# ENCODER0_REG_TOPAZHP_CORE_0 register map
Vendor: Texas Instruments
Registers are 32-bit, access per field, reset 0x0 unless marked. A register's access mark holds for its fields unless they carry their own. Offsets are as the file gives them; [hi:lo] are bit positions; {n}, {i} and the like mark numbered series; <NAME> marks a mode.

## ENCODER0_REG_TOPAZHP_CORE_0 (part 2 of 2)
0x174 ENCODER0_CR_MVCALC_COLOCATED reset 0x100
  [10:0] CR_COL_DIST_SCALE_FACT rw — Singed scaling value in range -1024 to +1023 used to calculate direct mode motion vectors from co-located motion vector [a value of 256 uses co-located motion vector without scaling]
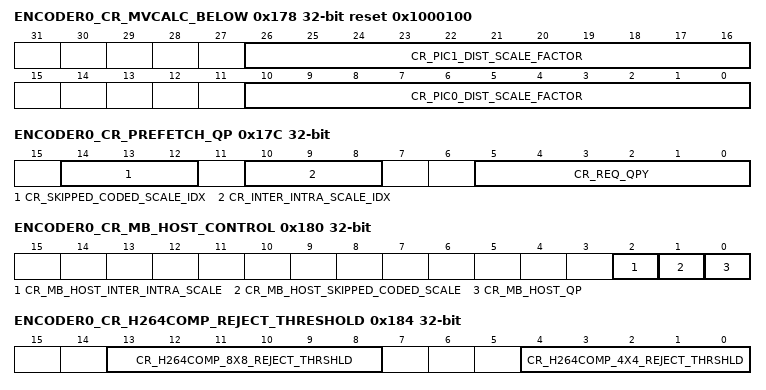
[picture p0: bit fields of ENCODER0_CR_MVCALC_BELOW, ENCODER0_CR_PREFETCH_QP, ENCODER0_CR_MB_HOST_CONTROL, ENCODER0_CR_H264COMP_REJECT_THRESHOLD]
0x178 ENCODER0_CR_MVCALC_BELOW reset 0x1000100
  [26:16] CR_PIC1_DIST_SCALE_FACTOR rw — Signed scaling factor in range -1024 to +1023 applied to below motion vector when calculating motion vector relative to reference picture 1
  [10:0] CR_PIC0_DIST_SCALE_FACTOR rw — Signed scaling factor in range -1024 to +1023 applied to below motion vector when calculating motion vector relative to reference picture 0 [intended for use when distance between frames when below motion vector was calculated is different from current distance between frames]
0x17C ENCODER0_CR_PREFETCH_QP — This register is used to set the requested QPy value at the start of the pipeline. Hardware keeps an internal version of requested QPy, which will propagate done the pipeline. Changes to this register will take effect at the start of the next kick.
  [14:12] CR_SKIPPED_CODED_SCALE_IDX rw — Index into skipped/coded scaling table
  [10:8] CR_INTER_INTRA_SCALE_IDX rw — Index into Inter/Intra scaling Table
  [5:0] CR_REQ_QPY rw — H
0x180 ENCODER0_CR_MB_HOST_CONTROL — Specify which macroblock parameters are valid in control structure read in from host
  [2] CR_MB_HOST_INTER_INTRA_SCALE rw — 0 - Inter/Intra scale table index for macroblock is specified by control registers
  [1] CR_MB_HOST_SKIPPED_CODED_SCALE rw — 0 - Skipped/Coded cost scaling for macroblock is specified by control registers
  [0] CR_MB_HOST_QP rw — 0 - Requested QP for macroblock [before CARC] is specified by control register [CR_REQ_QPY]
0x184 ENCODER0_CR_H264COMP_REJECT_THRESHOLD
  [13:8] CR_H264COMP_8X8_REJECT_THRSHLD rw — Threshold used to decide whether a 8x8 sub-block residual should be coded
  [4:0] CR_H264COMP_4X4_REJECT_THRSHLD rw — Threshold used to decide whether a 4x4 sub-block residual should be coded
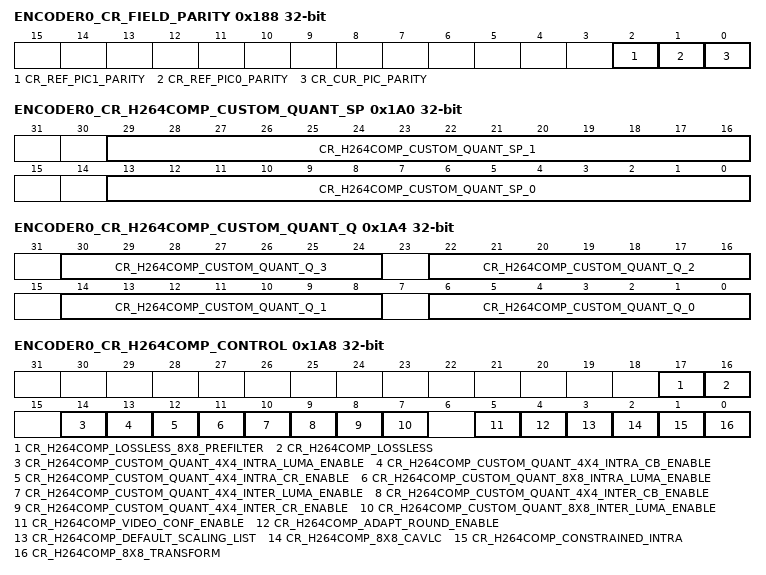
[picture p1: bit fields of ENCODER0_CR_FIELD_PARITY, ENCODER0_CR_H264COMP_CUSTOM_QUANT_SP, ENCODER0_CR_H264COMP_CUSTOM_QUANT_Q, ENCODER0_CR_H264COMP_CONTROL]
0x188 ENCODER0_CR_FIELD_PARITY
  [2] CR_REF_PIC1_PARITY rw — 0 - Top Field
  [1] CR_REF_PIC0_PARITY rw — 0 - Top Field
  [0] CR_CUR_PIC_PARITY rw — 0 - Top field
0x1A0 ENCODER0_CR_H264COMP_CUSTOM_QUANT_SP — This register is written repeatedly to store the Sp values for the Custom Quantisation Matrix. Two Sp values at a time are stored. The Sp values should be provided in raster order, with the 16 values for the 4x4 intra luma matrix provided first, followed by the 16 values for the 4x4 inter luma matrix, followed by the 16 values for the 4x4 intra Cb matrix, followed by the 16 values for the 4x4 inter Cb matrix, followed by the 16 values for the 4x4 intra Cr matrix, followed by the 16 values for the 4x4 inter Cr matrix, followed by the 64 values for the 8x8 intra luma matrix, followed by the 64 values for the 8x8 inter luma matrix. The 8x8 values do not need to be stored if use of the 8x8 transform is disabled. To store the full set of Sp values takes 112 register write accesses. To store only the 4x4 values takes 48 register write accesses. The format of this register is arranged such that Sp values packed 1 per 2 bytes in memory may be directly copied into the register.When read this register always returns 0x00000000.
  [29:16] CR_H264COMP_CUSTOM_QUANT_SP_1 rw — Sp value for Custom Quantisation Matrix.
  [13:0] CR_H264COMP_CUSTOM_QUANT_SP_0 rw — Sp value for Custom Quantisation Matrix.
0x1A4 ENCODER0_CR_H264COMP_CUSTOM_QUANT_Q — This register is written repeatedly to store the Q values for the Custom Quantisation Matrix. Four Q values at a time are stored. The Q values should be provided in raster order, with the 16 values for the 4x4 intra luma matrix provided first, followed by the 16 values for the 4x4 inter luma matrix, followed by the 16 values for the 4x4 intra Cb matrix, followed by the 16 values for the 4x4 inter Cb matrix, followed by the 16 values for the 4x4 intra Cr matrix, followed by the 16 values for the 4x4 inter Cr matrix, followed by the 64 values for the 8x8 intra luma matrix, followed by the 64 values for the 8x8 inter luma matrix. The 8x8 values do not need to be stored if use of the 8x8 transform is disabled. To store the full set of Q values takes 56 register write accesses. To store only the 4x4 values takes 24 register write accesses. The format of this register is arranged such that Q values packed 1 per byte in memory may be directly copied into the register.When read this register always returns 0x00000000.
  [8n+6:8n] CR_H264COMP_CUSTOM_QUANT_Q_{n} rw (n=0..3) — Q value for Custom Quantisation Matrix.
0x1A8 ENCODER0_CR_H264COMP_CONTROL
  [17] CR_H264COMP_LOSSLESS_8X8_PREFILTER rw — Controls whether the pre-filter operation should be performed as part of the Intra8x8 prediction in Lossless Mode.
  [16] CR_H264COMP_LOSSLESS rw — Controls support of lossless encoding in H.264.
  [14] CR_H264COMP_CUSTOM_QUANT_4X4_INTRA_LUMA_ENABLE rw — Controls the use of Custom Quantisation Tables for the following block types:
  [13] CR_H264COMP_CUSTOM_QUANT_4X4_INTRA_CB_ENABLE rw — Controls the use of Custom Quantisation Tables for the following block types:
  [12] CR_H264COMP_CUSTOM_QUANT_4X4_INTRA_CR_ENABLE rw — Controls the use of Custom Quantisation Tables for the following block types:
  [11] CR_H264COMP_CUSTOM_QUANT_8X8_INTRA_LUMA_ENABLE rw — Controls the use of Custom Quantisation Tables for the following block types:
  [10] CR_H264COMP_CUSTOM_QUANT_4X4_INTER_LUMA_ENABLE rw — Controls the use of Custom Quantisation Tables for the following block types:
  [9] CR_H264COMP_CUSTOM_QUANT_4X4_INTER_CB_ENABLE rw — Controls the use of Custom Quantisation Tables for the following block types:
  [8] CR_H264COMP_CUSTOM_QUANT_4X4_INTER_CR_ENABLE rw — Controls the use of Custom Quantisation Tables for the following block types:
  [7] CR_H264COMP_CUSTOM_QUANT_8X8_INTER_LUMA_ENABLE rw — Controls the use of Custom Quantisation Tables for the following block types:
  [5] CR_H264COMP_VIDEO_CONF_ENABLE rw — 0: Video conference support is disabled
  [4] CR_H264COMP_ADAPT_ROUND_ENABLE rw — 0: Use Fixed Rounding
  [3] CR_H264COMP_DEFAULT_SCALING_LIST rw — Controls the choice between FLAT and DEFAULT scaling lists.
  [2] CR_H264COMP_8X8_CAVLC rw — 0: If transform size is 8x8, CABAC mode is used, so don't need to re-order block coefficients into 4x4 blocks.
  [1] CR_H264COMP_CONSTRAINED_INTRA rw — 0: Intra prediction can use boundary pixels from Inter MBs
  [0] CR_H264COMP_8X8_TRANSFORM rw — 0: Use 4x4 transform for Inter MB, disable Luma Intra 8x8 prediction
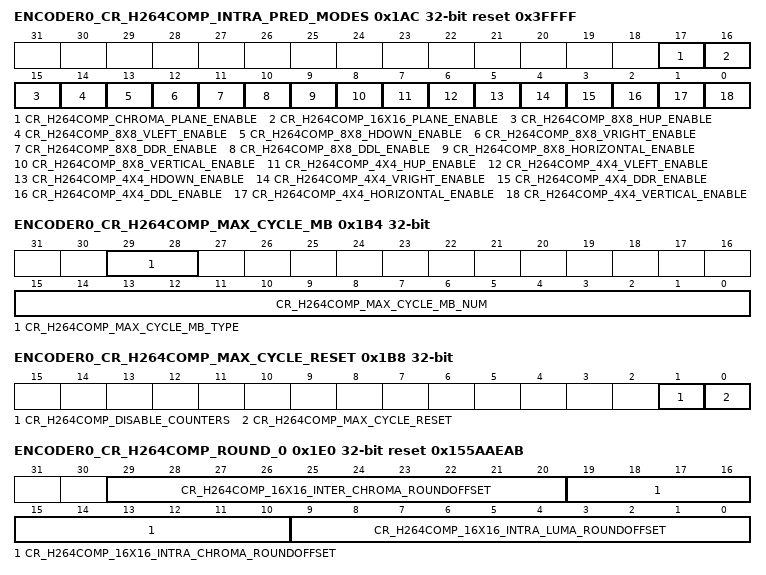
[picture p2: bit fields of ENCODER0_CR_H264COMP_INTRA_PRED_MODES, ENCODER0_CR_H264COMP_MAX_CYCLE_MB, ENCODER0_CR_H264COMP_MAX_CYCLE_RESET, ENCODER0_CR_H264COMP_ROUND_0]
0x1AC ENCODER0_CR_H264COMP_INTRA_PRED_MODES reset 0x3FFFF
  [17] CR_H264COMP_CHROMA_PLANE_ENABLE rw, [16] CR_H264COMP_16X16_PLANE_ENABLE rw, [15] CR_H264COMP_8X8_HUP_ENABLE rw, [14] CR_H264COMP_8X8_VLEFT_ENABLE rw, [13] CR_H264COMP_8X8_HDOWN_ENABLE rw, [12] CR_H264COMP_8X8_VRIGHT_ENABLE rw, [11] CR_H264COMP_8X8_DDR_ENABLE rw, [10] CR_H264COMP_8X8_DDL_ENABLE rw, [9] CR_H264COMP_8X8_HORIZONTAL_ENABLE rw, [8] CR_H264COMP_8X8_VERTICAL_ENABLE rw, [7] CR_H264COMP_4X4_HUP_ENABLE rw, [6] CR_H264COMP_4X4_VLEFT_ENABLE rw, [5] CR_H264COMP_4X4_HDOWN_ENABLE rw, [4] CR_H264COMP_4X4_VRIGHT_ENABLE rw, [3] CR_H264COMP_4X4_DDR_ENABLE rw, [2] CR_H264COMP_4X4_DDL_ENABLE rw, [1] CR_H264COMP_4X4_HORIZONTAL_ENABLE rw, [0] CR_H264COMP_4X4_VERTICAL_ENABLE rw
0x1B0 ENCODER0_CR_H264COMP_MAX_CYCLE_COUNT
  [15:0] CR_H264COMP_MAX_CYCLE_COUNT rw — The worst case cycle count of the MB processing for the cmprs module
0x1B4 ENCODER0_CR_H264COMP_MAX_CYCLE_MB
  [29:28] CR_H264COMP_MAX_CYCLE_MB_TYPE rw — It indicates the MB type: I, P or B of the worst MB processing cycle number
  [15:0] CR_H264COMP_MAX_CYCLE_MB_NUM rw — Number of the macroblock with the worst MB cycle count
0x1B8 ENCODER0_CR_H264COMP_MAX_CYCLE_RESET
  [1] CR_H264COMP_DISABLE_COUNTERS rw — When this bit is set to a 1, the max cycle counters should not be clocked
  [0] CR_H264COMP_MAX_CYCLE_RESET rw — To be used by MTX to reset the max cycle registers [0x01b0 and 0x01b4]
0x1BC ENCODER0_CR_H264COMP4X4_PRED_CRC rw
  [31:0] CR_H264COMP4X4_PRED_CRC — CRC value of the 4x4 prediction blocks
0x1C0 ENCODER0_CR_H264COMP4X4_COEFFS_CRC rw
  [31:0] CR_H264COMP4X4_COEFFS_CRC — CRC value of the 4x4 quantised coefficients
0x1C4 ENCODER0_CR_H264COMP4X4_RECON_CRC rw
  [31:0] CR_H264COMP4X4_RECON_CRC — CRC value of the 4x4 reconstructed blocks
0x1C8 ENCODER0_CR_H264COMP8X8_PRED_CRC rw
  [31:0] CR_H264COMP8X8_PRED_CRC — CRC value of the 8x8 prediction blocks
0x1CC ENCODER0_CR_H264COMP8X8_COEFFS_CRC rw
  [31:0] CR_H264COMP8X8_COEFFS_CRC — CRC value of the 8x8 quantised coefficients
0x1D0 ENCODER0_CR_H264COMP8X8_RECON_CRC rw
  [31:0] CR_H264COMP8X8_RECON_CRC — CRC value of the 8x8 reconstructed blocks
0x1D4 ENCODER0_CR_H264COMP16X16_PRED_CRC rw
  [31:0] CR_H264COMP16X16_PRED_CRC — CRC value of the 16x16 prediction blocks
0x1D8 ENCODER0_CR_H264COMP16X16_COEFFS_CRC rw
  [31:0] CR_H264COMP16X16_COEFFS_CRC — CRC value of the 16x16 quantised coefficients
0x1DC ENCODER0_CR_H264COMP16X16_RECON_CRC rw
  [31:0] CR_H264COMP16X16_RECON_CRC — CRC value of the 16x16 reconstructed blocks
0x1E0 ENCODER0_CR_H264COMP_ROUND_0 reset 0x155AAEAB — The rounding offset values should be written to / read from these registers between slices when the slice type is changed.A sequence of 3 reads or writes to this register should be performed in the following order: offset_1 -> offset_2 -> offset_3. Provided that a full sequence of 3 reads is performed the data stored will be left unchanged. The intra values all reset to 0x2AB (=1/3) and the inter values all reset to 0x155 (=1/6). They can also all be initialised to these values using a single write to ROUNDOFFSET_INITIALISE.
  [29:20] CR_H264COMP_16X16_INTER_CHROMA_ROUNDOFFSET rw — Adaptive rounding offset values for 16x16 inter chroma.
  [19:10] CR_H264COMP_16X16_INTRA_CHROMA_ROUNDOFFSET rw — Adaptive rounding offset values for 16x16 intra chroma.
  [9:0] CR_H264COMP_16X16_INTRA_LUMA_ROUNDOFFSET rw — Adaptive rounding offset values for 16x16 intra luma.
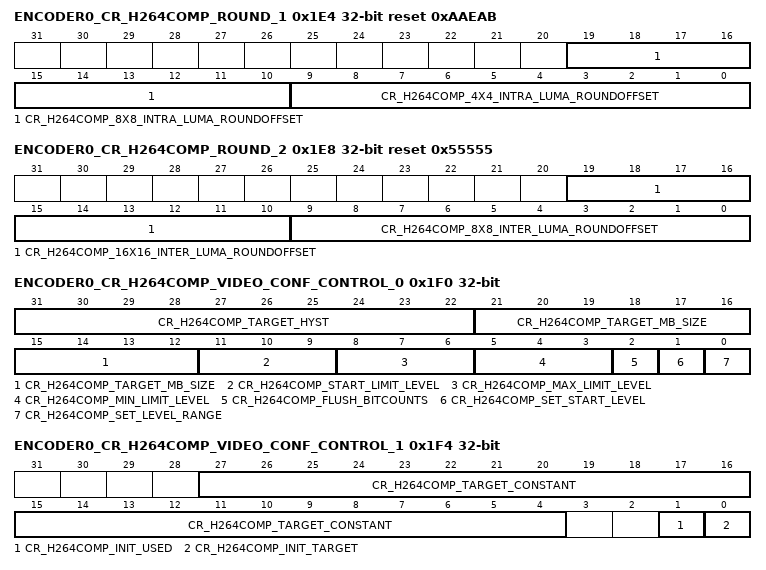
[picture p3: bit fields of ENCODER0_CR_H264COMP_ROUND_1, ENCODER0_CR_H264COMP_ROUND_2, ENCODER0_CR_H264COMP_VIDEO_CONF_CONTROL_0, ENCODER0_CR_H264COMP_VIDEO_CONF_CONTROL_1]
0x1E4 ENCODER0_CR_H264COMP_ROUND_1 reset 0xAAEAB — A sequence of 4 reads or writes to this register should be performed in the following order: offset_0 -> offset_1 -> offset_2 -> offset_3. Provided that a full sequence of 4 reads is performed the data stored will be left unchanged. The intra values all reset to 0x2AB (=1/3). They can also all be initialised to these values using a single write to ROUNDOFFSET_INITIALISE.
  [19:10] CR_H264COMP_8X8_INTRA_LUMA_ROUNDOFFSET rw — Adaptive rounding offset values for 8x8 intra luma.
  [9:0] CR_H264COMP_4X4_INTRA_LUMA_ROUNDOFFSET rw — Adaptive rounding offset values for 4x4 intra luma.
0x1E8 ENCODER0_CR_H264COMP_ROUND_2 reset 0x55555 — A sequence of 4 reads or writes to this register should be performed in the following order: offset_0 -> offset_1 -> offset_2 -> offset_3. Provided that a full sequence of 4 reads is performed the data stored will be left unchanged. The intra values all reset to 0x155 (=1/6). They can also all be initialised to these values using a single write to ROUNDOFFSET_INITIALISE.
  [19:10] CR_H264COMP_16X16_INTER_LUMA_ROUNDOFFSET rw — Adaptive rounding offset values for 16x16 inter luma.
  [9:0] CR_H264COMP_8X8_INTER_LUMA_ROUNDOFFSET rw — Adaptive rounding offset values for 8x8 inter luma.
0x1EC ENCODER0_CR_H264COMP_ROUND_INIT — Writing 0x1 to this register causes all of the rounding offsets to be initialised to their default values, which are 0x2AB (=1/3) for intra, and 0x155 (=1/6) for inter.
  [0] CR_H264COMP_ROUNDOFFSET_INITIALISE rw — 0: No effect
0x1F0 ENCODER0_CR_H264COMP_VIDEO_CONF_CONTROL_0 rw — Double buffered register for configuring the macroblock size control for video conference support. The feature is disabled when H264COMP_CONTROL/H264COMP_VIDEO_CONF_ENABLE = 0. 0
  [31:22] CR_H264COMP_TARGET_HYST — The number of bits below the target the used count has to be before the limit_level is decremented, see description for TARGET_MB_SIZE.
  [21:12] CR_H264COMP_TARGET_MB_SIZE — The target macroblock size to be achieved in bits cross a frame.
  [11:9] CR_H264COMP_START_LIMIT_LEVEL — Limit level to be used for the first macroblock in the BU.
  [8:6] CR_H264COMP_MAX_LIMIT_LEVEL — Maximum limit level to be used during the BU.
  [5:3] CR_H264COMP_MIN_LIMIT_LEVEL — Minimum limit level to be used during the BU.
  [2] CR_H264COMP_FLUSH_BITCOUNTS — 0: The FIFO which buffers the bitcounts between the VLC and the H264comp is NOT flushed.
  [1] CR_H264COMP_SET_START_LEVEL — 0: The limit level is allowed to increment or decrement depending on the bitcount target on all macroblocks in the BU, continuing on from the previous BU.
  [0] CR_H264COMP_SET_LEVEL_RANGE — 0: The maximum and minimum limit level are left unchanged.
0x1F4 ENCODER0_CR_H264COMP_VIDEO_CONF_CONTROL_1 — Double buffered register for configuring the macroblock size control for video conference support.
  [27:4] CR_H264COMP_TARGET_CONSTANT rw — Constant used in the calculation of the bitrate target, see TARGET_MB_SIZE.
  [1] CR_H264COMP_INIT_USED rw — 0: The count of bits used increases as usual on every macroblock.
  [0] CR_H264COMP_INIT_TARGET rw — 0: The bitcount target is incremented by TARGET_MB_SIZE on every macroblock.
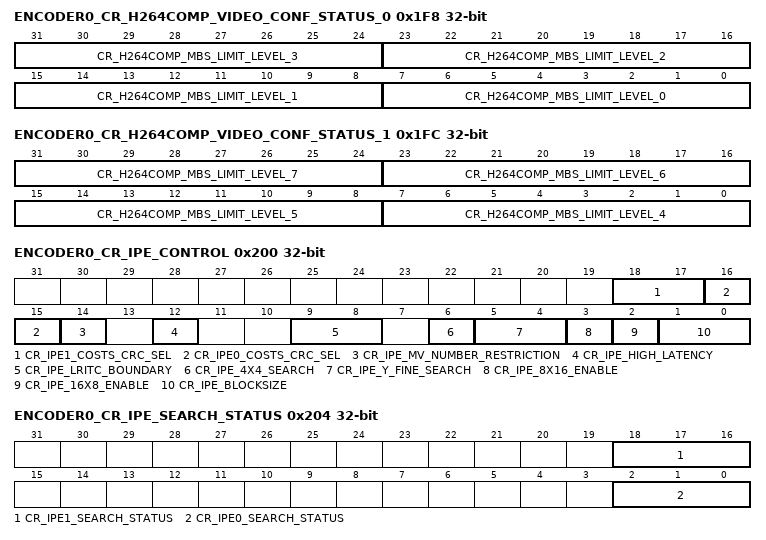
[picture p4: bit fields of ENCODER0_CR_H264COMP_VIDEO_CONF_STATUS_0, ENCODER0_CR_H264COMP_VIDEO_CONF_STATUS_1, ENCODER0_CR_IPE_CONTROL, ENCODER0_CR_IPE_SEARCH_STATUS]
0x1F8 ENCODER0_CR_H264COMP_VIDEO_CONF_STATUS_0 ro — Double buffered register providing status on how many macroblocks in the last BU were encoded at each limit level when video conference support is in use. This register will only update if video conference support is enabled.
  [8n+7:8n] CR_H264COMP_MBS_LIMIT_LEVEL_{n} (n=0..3) — The number of macroblocks in the last BU that were coded using LIMIT_LEVEL_{n}.
0x1FC ENCODER0_CR_H264COMP_VIDEO_CONF_STATUS_1 ro — Double buffered register providing status on how many macroblocks in the last BU were encoded at each limit level when video conference support is in use. This register will only update if video conference support is enabled.
  [8n-25:8n-32] CR_H264COMP_MBS_LIMIT_LEVEL_{n} (n=4..7) — The number of macroblocks in the last BU that were coded using LIMIT_LEVEL_{n}.
0x200 ENCODER0_CR_IPE_CONTROL
  [18:17] CR_IPE1_COSTS_CRC_SEL rw — selects between the different crcs, can be switched wile running, all crcs exist just share register space
  [16:15] CR_IPE0_COSTS_CRC_SEL rw — selects between the different crcs, can be switched wile running, all crcs exist just share register space
  [14] CR_IPE_MV_NUMBER_RESTRICTION rw
  [12] CR_IPE_HIGH_LATENCY rw — 0 : IPE 8x8 spatial candidates include previous 8x8 block
  [9:8] CR_IPE_LRITC_BOUNDARY rw — This field +1 defines number of boundary pixels LRITC needs to fetch for each block request.
  [6] CR_IPE_4X4_SEARCH rw — If IPE_BLOCKSIZE enables 4x4 search
  [5:4] CR_IPE_Y_FINE_SEARCH rw
  [3] CR_IPE_8X16_ENABLE rw — 0 : Disable 8x16 motion vector block size detection
  [2] CR_IPE_16X8_ENABLE rw — 0 : Disable 16x8 motion vector block size detection
  [1:0] CR_IPE_BLOCKSIZE rw
0x204 ENCODER0_CR_IPE_SEARCH_STATUS
  [18:16] CR_IPE1_SEARCH_STATUS rw — 000: Finished recieving candidates/Idle between MB's
  [2:0] CR_IPE0_SEARCH_STATUS rw — 000: Finished recieving candidates/Idle between MB's
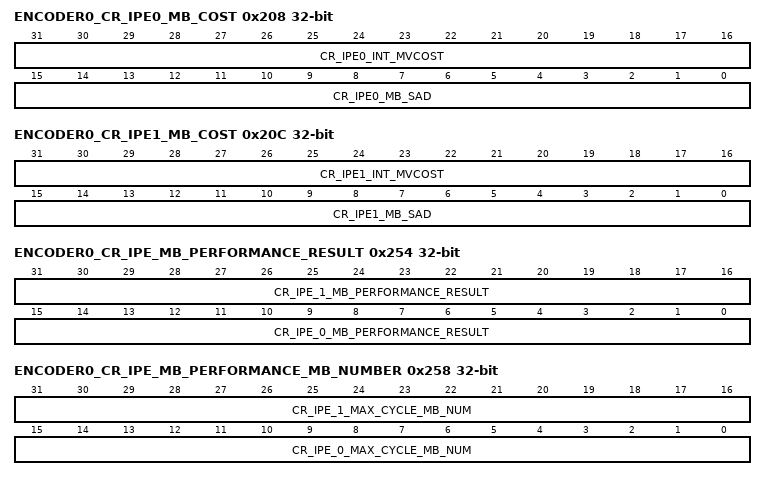
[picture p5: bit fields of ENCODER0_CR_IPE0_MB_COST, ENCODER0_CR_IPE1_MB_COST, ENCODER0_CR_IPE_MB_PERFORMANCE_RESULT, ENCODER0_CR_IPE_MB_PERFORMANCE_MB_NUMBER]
0x208 ENCODER0_CR_IPE0_MB_COST rw
  [31:16] CR_IPE0_INT_MVCOST — Total motion vector cost for IPE 0
  [15:0] CR_IPE0_MB_SAD — Total Sum of Absolute Differences value for IPE 0
0x20C ENCODER0_CR_IPE1_MB_COST rw
  [31:16] CR_IPE1_INT_MVCOST — Total motion vector cost for IPE 1
  [15:0] CR_IPE1_MB_SAD — Total Sum of Absolute Differences value for IPE 1
0x240 ENCODER0_CR_IPE0_BESTMV_CRC rw
  [31:0] CR_IPE0_BESTMV_CRC — IPE 0 CRC best mv data output.
0x244 ENCODER0_CR_IPE1_BESTMV_CRC rw
  [31:0] CR_IPE1_BESTMV_CRC — IPE 1 CRC best mv data output.
0x248 ENCODER0_CR_IPE0_COSTS_CRC rw
  [31:0] CR_IPE0_COSTS_CRC — IPE costs crc, crc for ipe costs, there is a select register to select between 4x4, 8x8 or 16x16 costs.
0x24C ENCODER0_CR_IPE1_COSTS_CRC rw
  [31:0] CR_IPE1_COSTS_CRC — IPE costs crc, for the second ipe, there is a select register to select between 4x4, 8x8 or 16x16 costs.
0x250 ENCODER0_CR_IPE_MB_PERFORMANCE_CLEAR — IPE macro block performance clear register
  [0] CR_IPE_MB_PERFORMANCE_CLEAR wo — Clear the ipe mb performance registers
0x254 ENCODER0_CR_IPE_MB_PERFORMANCE_RESULT ro — IPE macro block performance maximum cycle count (based on last done from either IPE 0 or IPE 1)
  [31:16] CR_IPE_1_MB_PERFORMANCE_RESULT — Maximum IPE 1 cycle count
  [15:0] CR_IPE_0_MB_PERFORMANCE_RESULT — Maximum IPE 0 cycle count
0x258 ENCODER0_CR_IPE_MB_PERFORMANCE_MB_NUMBER ro — IPE macro block performance macro block number
  [31:16] CR_IPE_1_MAX_CYCLE_MB_NUM — Number of macroblock with the worst case cycle count
  [15:0] CR_IPE_0_MAX_CYCLE_MB_NUM — Number of macroblock with the worst case cycle count
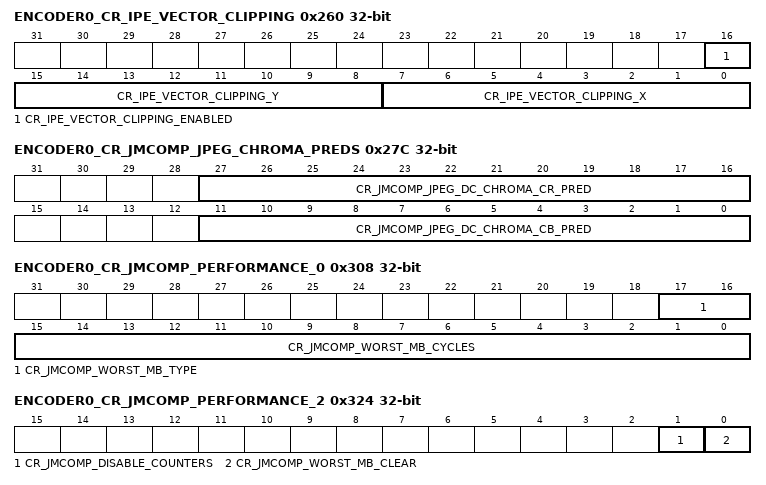
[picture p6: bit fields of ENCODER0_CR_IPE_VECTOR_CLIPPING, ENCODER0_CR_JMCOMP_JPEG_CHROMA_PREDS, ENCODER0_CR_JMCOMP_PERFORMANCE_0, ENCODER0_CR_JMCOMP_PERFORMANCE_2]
0x260 ENCODER0_CR_IPE_VECTOR_CLIPPING — This register contains the maximum X & Y vectors (normally used for MPEG4 and H263 encoding). The IPE module needs to take these values into account when searching for the best vector. This register is used by both the Prefetch Sequencer (to ensure initial candidates are within the clipping range) and by IPE (to ensure fine search and 4x4 search doesn't extend outside the clipping area), and by SPE (to ensure sub-pixel search doesn't extend outside the clipping area).
  [16] CR_IPE_VECTOR_CLIPPING_ENABLED rw — 0 : Ignore IPE vector clipping registers [only clip to maximum search range supported by hardware]
  [15:8] CR_IPE_VECTOR_CLIPPING_Y rw — Maximum Y vector [integer resolution]
  [7:0] CR_IPE_VECTOR_CLIPPING_X rw — Maximum X vector [integer resolution]
0x270 ENCODER0_CR_JMCOMP_CONTROL reset 0x8000
  [15] CR_JMCOMP_AC_ENABLE rw
0x278 ENCODER0_CR_JMCOMP_JPEG_LUMA_PRED
  [11:0] CR_JMCOMP_JPEG_DC_LUMA_PRED rw — Current Luma DC prediction
0x27C ENCODER0_CR_JMCOMP_JPEG_CHROMA_PREDS
  [27:16] CR_JMCOMP_JPEG_DC_CHROMA_CR_PRED rw — Current Cr DC prediction
  [11:0] CR_JMCOMP_JPEG_DC_CHROMA_CB_PRED rw — Current Cb DC prediction
{0x280+4i} ENCODER0_CR_JMCOMP_LUMA_QUANTISER_{i:02} rw (i=0..15)
  [31:24] CR_JMCOMP_LUMA_QUANT — 64 JPEG Luma quantisation coefficients
{0x2C0+4i} ENCODER0_CR_JMCOMP_CHROMA_QUANTISER_{i:02} rw (i=0..15)
  [31:24] CR_JMCOMP_CHROMA_QUANT — 64 JPEG Chroma quantisation coefficients [same coefficients used for Cb and Cr]
0x300 ENCODER0_CR_JMCOMP_CRC rw
  [31:0] CR_JMCOMP_CRC_OUT — CRC value of the current data that is written to the ESB
0x304 ENCODER0_CR_JMCOMP_VLC_CRC rw — CRC for data outputted to VLC
  [31:0] CR_JMCOMP_VLC_IF_CRC — CRC value of the coded data that is sent to the VLC
0x308 ENCODER0_CR_JMCOMP_PERFORMANCE_0 ro
  [17:16] CR_JMCOMP_WORST_MB_TYPE — The MB type of the worst MB.
  [15:0] CR_JMCOMP_WORST_MB_CYCLES — The number of cycles taken to process the worst MB.
0x30C ENCODER0_CR_JMCOMP_CRC_RDATA ro — CRCs for the current data read from the ESB
  [31:0] CR_JMCOMP_CRC_RDATA_OUT
0x310 ENCODER0_CR_JMCOMP_CRC_CARC ro — CRCs for the CARC data generated by the JMCOMP (H264 only)
  [31:0] CR_JMCOMP_CRC_CARC_OUT — CRCs for the CARC data
0x320 ENCODER0_CR_JMCOMP_PERFORMANCE_1 ro
  [15:0] CR_JMCOMP_WORST_MB_NUM — The linear MB number of the worst MB.
0x324 ENCODER0_CR_JMCOMP_PERFORMANCE_2
  [1] CR_JMCOMP_DISABLE_COUNTERS rw
  [0] CR_JMCOMP_WORST_MB_CLEAR rw — Writing this single bit with the value '1' clears both performance registers and resets the worst MB Num counter
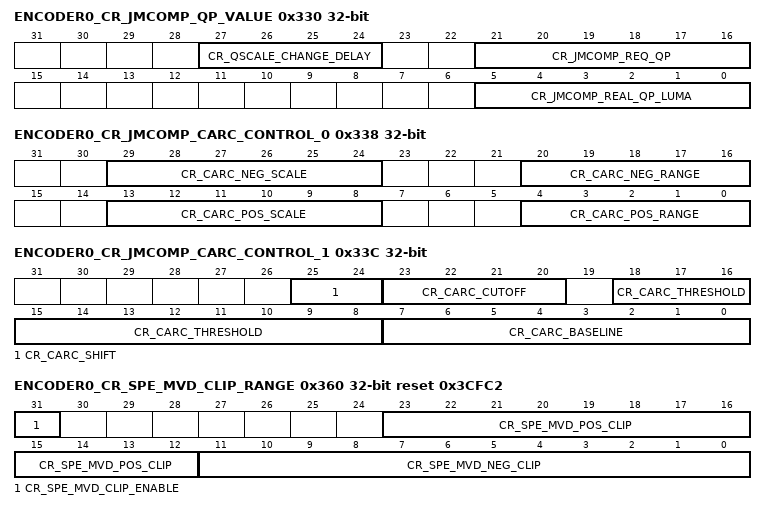
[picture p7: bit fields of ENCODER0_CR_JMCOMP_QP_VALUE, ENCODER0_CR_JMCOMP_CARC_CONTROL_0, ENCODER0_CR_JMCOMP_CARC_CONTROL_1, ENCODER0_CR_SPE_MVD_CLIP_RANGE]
0x330 ENCODER0_CR_JMCOMP_QP_VALUE — Register with the encoded QP value, software reads it to check if next QP change is possible
  [27:24] CR_QSCALE_CHANGE_DELAY rw — Number of macroblocks in which requested QScale is different from current QScale, but delta value hasn't been changed due to macroblock type [count is reset to zero if requested QScale is same as current QScale, or if force qscale signal sent to frontend of pipeline]
  [21:16] CR_JMCOMP_REQ_QP rw — QP value requested from prefetch sequencer interface
  [5:0] CR_JMCOMP_REAL_QP_LUMA rw — QP value with which MB was encoded
0x334 ENCODER0_CR_JMCOMP_QSCALE_CHANGE reset 0xF
  [3:0] CR_QSCALE_CHANGE_THRESHOLD rw — If QSCALE_CHANGE_DELAY increments above this threshold, a signal is sent to front end of pipeline to force QSCALE change
0x338 ENCODER0_CR_JMCOMP_CARC_CONTROL_0
  [29:24] CR_CARC_NEG_SCALE rw — Unsigned scale factor for H264 content adaptive rate control when complexity is less than CARC_BASELINE.
  [20:16] CR_CARC_NEG_RANGE rw — Unsigned integer being the maximum amount that the H264 content adaptive rate control will decrease the qp by.
  [13:8] CR_CARC_POS_SCALE rw — Unsigned scale factor for H264 content adaptive rate control when complexity is greater than CARC_BASELINE.
  [4:0] CR_CARC_POS_RANGE rw — Unsigned integer being the maximum amount that the H264 content adaptive rate control will increase the qp by.
0x33C ENCODER0_CR_JMCOMP_CARC_CONTROL_1
  [25:24] CR_CARC_SHIFT rw — When calculating the change in qp as a result of CARC, this controls the size of the right shift of the applied.
  [23:20] CR_CARC_CUTOFF rw — Specifies the subset of coefficients in an 8x8 block that count towards the CARC complexity metric.
  [18:8] CR_CARC_THRESHOLD rw — Threshold applied to the DCT coefficients before they count towards the CARC complexity.
  [7:0] CR_CARC_BASELINE rw — Unsigned value which is the point at which the CARC qp modification switches from negative to positive scales.
0x340 ENCODER0_CR_JMCOMP_CARC_COEFF_TOTAL rw
  [31:0] CR_CARC_COEFF_TOTAL — Running total count of the CARC coefficient counts.
0x344 ENCODER0_CR_SPE_ZERO_THRESH
  [4:0] CR_SPE_ZERO_THRESH rw — Value multiplied by QPy to form ZERO_THRESHOLD
0x348 ENCODER0_CR_SPE0_BEST_SAD_SIGNATURE rw
  [31:0] CR_SPE0_BEST_SAD_SIGNATURE — This is a 96 bit input crc , input is 4 best_8x8_cost_tile0/1/2/3 values &amp; best_cb_sad &amp; best_cr_sad concatednated on spe_done.
0x34C ENCODER0_CR_SPE1_BEST_SAD_SIGNATURE rw
  [31:0] CR_SPE1_BEST_SAD_SIGNATURE — This is a 96 bit input crc , input is 4 best_8x8_cost_tile0/1/2/3 values &amp; best_cb_sad &amp; best_cr_sad concatednated on spe_done.
0x350 ENCODER0_CR_SPE0_BEST_INDEX_SIGNATURE rw
  [31:0] CR_SPE0_BEST_INDEX_SIGNATURE — This is a CRC for best index of every 4x4 block
0x354 ENCODER0_CR_SPE1_BEST_INDEX_SIGNATURE rw
  [31:0] CR_SPE1_BEST_INDEX_SIGNATURE — This is a CRC for best index of every 4x4 block
0x358 ENCODER0_CR_SPE_INTRA_COST_SIGNATURE rw
  [31:0] CR_SPE_INTRA_COST_SIGNATURE — This is a 32 bit input crc , input is intra_cost value calculated in MPEG4/H263 modes on spe_done , in H264 mode input will be 0.
0x360 ENCODER0_CR_SPE_MVD_CLIP_RANGE reset 0x3CFC2 — Specifies the range for MV differential clipping in H263 profile 0.
  [31] CR_SPE_MVD_CLIP_ENABLE rw — 0 : Don't use SPE_MVD_CLIP registers
  [23:12] CR_SPE_MVD_POS_CLIP rw — Signed largest positive difference between calculated MV and predicted MV in 1/4 pel resolution [mainly used for H263 profile 0]
  [11:0] CR_SPE_MVD_NEG_CLIP rw — Signed largest negative difference between calculated MV and predicted MV in 1/4 pel resolution [mainly used for H263 profile 0]
0x364 ENCODER0_CR_SPE_SUBPEL_RESOLUTION
  [1:0] CR_SPE_SUBPEL_RESOLUTION rw — 0 : 1/4 pixel resolution in H264 [1/2 pixel resolution for MPEG4]
0x368 ENCODER0_CR_SPE0_MV_SIZE_SIGNATURE rw
  [31:0] CR_SPE0_MV_SIZE_SIGNATURE — This is a 32 bit input crc , input is spe_mv_size_16x16 &amp; spe_mv_size_16x8 &amp; spe_mv_size_8x16 &amp; spe_mv_size_8x8_t0 &amp; spe_mv_size_8x8_t1 &amp; spe_mv_size_8x8_t2 &amp; spe_mv_size_8x8_t3 concatednated on spe_done.
0x36C ENCODER0_CR_SPE1_MV_SIZE_SIGNATURE rw
  [31:0] CR_SPE1_MV_SIZE_SIGNATURE — This is a 32 bit input crc , input is spe_mv_size_16x16 &amp; spe_mv_size_16x8 &amp; spe_mv_size_8x16 &amp; spe_mv_size_8x8_t0 &amp; spe_mv_size_8x8_t1 &amp; spe_mv_size_8x8_t2 &amp; spe_mv_size_8x8_t3 concatednated on spe_done.
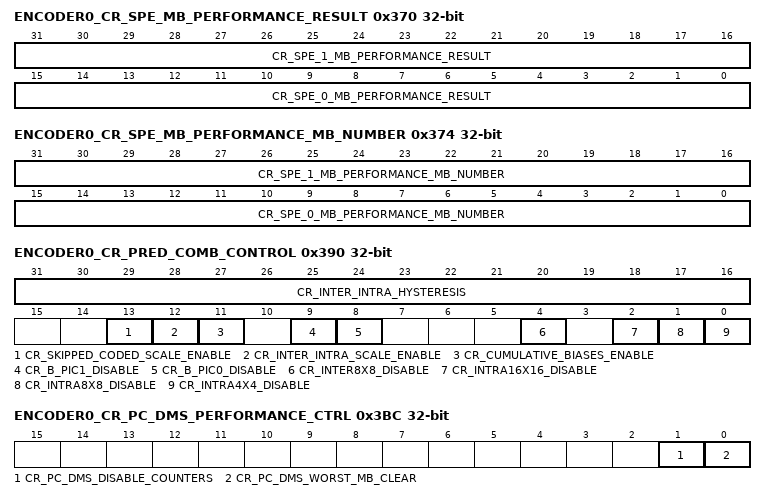
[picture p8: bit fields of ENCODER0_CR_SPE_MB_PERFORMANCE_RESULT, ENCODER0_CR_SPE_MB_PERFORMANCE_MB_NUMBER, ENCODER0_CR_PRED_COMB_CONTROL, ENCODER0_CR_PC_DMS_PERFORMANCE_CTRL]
0x370 ENCODER0_CR_SPE_MB_PERFORMANCE_RESULT ro
  [31:16] CR_SPE_1_MB_PERFORMANCE_RESULT — The worst case cycle count of the MB processing for both SPE module [based on last SPE module to set done]
  [15:0] CR_SPE_0_MB_PERFORMANCE_RESULT — The worst case cycle count of the MB processing for both SPE module [based on last SPE module to set done]
0x374 ENCODER0_CR_SPE_MB_PERFORMANCE_MB_NUMBER ro
  [31:16] CR_SPE_1_MB_PERFORMANCE_MB_NUMBER — Number of the macroblock with the worst case cycle count
  [15:0] CR_SPE_0_MB_PERFORMANCE_MB_NUMBER — Number of the macroblock with the worst case cycle count
0x378 ENCODER0_CR_SPE_MB_PERFORMANCE_CLEAR
  [0] CR_SPE_MB_PERFORMANCE_CLEAR wo — To be used by software to reset the SPE max cycle registers
0x37C ENCODER0_CR_PC_TOTAL_COSTS_SIGNATURE rw
  [31:0] CR_PC_TOTAL_COSTS_SIGNATURE — This is a 128 bit input crc , input is sub_mb_type_cost_0[12 bits ] &amp; sub_mb_type_cost_1[12 bits ] &amp; sub_mb_type_cost_2[12 bits ] &amp; sub_mb_type_cost_3[12 bits ] &amp;
0x380 ENCODER0_CR_PC_INTER_REGS_SIGNATURE rw
  [31:0] CR_PC_INTER_REGS_SIGNATURE — This is a 96 bit input crc , input is
0x384 ENCODER0_CR_PC_INTRA_REGS_SIGNATURE rw
  [31:0] CR_PC_INTRA_REGS_SIGNATURE — This is a 96 bit input crc , input is
0x388 ENCODER0_CR_PC_HW_OUTPUT_SIGNATURE rw
  [31:0] CR_PC_HW_OUTPUT_SIGNATURE — This is a 32 bit input crc , input is pc_mb_type[2 bits] &amp; pc_intra_size[2 bits] &amp; pc_inter_direction0[2 bits] &amp; pc_inter_direction1[2 bits] &amp; pc_inter_direction2[2 bits] &amp; pc_inter_direction3[2 bits] &amp; pc_inter_direct[4 bits] &amp; pc_inter_size_16x16 [1 bit] &amp; pc_inter_size_16x8[1 bit] &amp; pc_inter_size_8x16[1 bit] &amp; pc_inter_size8x8[4 bits] &amp; pc_zero_bit_reg[6 bits] concatednated on pc_done.
0x38C ENCODER0_CR_PC_COSTS_16X8_SIGNATURE rw
  [31:0] CR_PC_COSTS_16X8_SIGNATURE
0x390 ENCODER0_CR_PRED_COMB_CONTROL
  [31:16] CR_INTER_INTRA_HYSTERESIS rw — Unsigned hysteresis bias used to minimise the number of occasions MB coding mode switches between Inter prediction and Intra prediction.
  [13] CR_SKIPPED_CODED_SCALE_ENABLE rw — 1 : Coded cost [i.e.
  [12] CR_INTER_INTRA_SCALE_ENABLE rw — 1 : The inter and intra costs will be scaled by the appropriate values from the INTER_INTRA_SCALE_TABLE, before deciding making the inter/intra decision
  [11] CR_CUMULATIVE_BIASES_ENABLE rw
  [9] CR_B_PIC1_DISABLE rw
  [8] CR_B_PIC0_DISABLE rw
  [4] CR_INTER8X8_DISABLE rw — 0 : Allow an SPE tile which is bigger than 8x8 to be split into 8x8 prediction tiles
  [2] CR_INTRA16X16_DISABLE rw — 0 : Allow Intra 16x16 to be selected
  [1] CR_INTRA8X8_DISABLE rw — 0 : Allow Intra 8x8 to be selected
  [0] CR_INTRA4X4_DISABLE rw — 0 : Allow Intra 4x4 to be selected
0x394 ENCODER0_CR_PC_COSTS_8X16_SIGNATURE rw
  [31:0] CR_PC_COSTS_8X16_SIGNATURE
0x398 ENCODER0_CR_PC_COSTS_8X8_SIGNATURE rw
  [31:0] CR_PC_COSTS_8X8_SIGNATURE
0x39C ENCODER0_CR_PRED_BU_STAT_UPDATE
  [0] CR_FORCE_BU_STAT_UPDATE rw — Normally the rate control registers in 0x3A0 to 0x3AC are updated at the start of the next basic unit.
0x3A0 ENCODER0_CR_BEST_INTER_BU_SAD
  [30:0] CR_BEST_INTER_BU_SAD rw — Sum of the best inter mode SAD or SATD per macroblock [if Inter is selected as the MB type, else add 0], accumulated for a basic unit [the register is double buffered so that the value read is the sum from the previous BU, whilst an internal register accumulates the sum for the current BU].
0x3A4 ENCODER0_CR_BEST_INTER_BU_COST rw
  [31:0] CR_BEST_INTER_BU_COST — Signed sum of the best inter mode cost [including SAD, MV cost and Inter bias] per macroblock [if Inter is selected as the MB type, else add 0], accumulated for a basic unit [the register is double buffered so that the value read is the sum from the previous BU, whilst an internal register accumulates the sum for the current BU].
0x3A8 ENCODER0_CR_BEST_INTRA_BU_SAD
  [30:0] CR_BEST_INTRA_BU_SAD rw — Sum of the best intra mode SAD or SATD per macroblock [if Intra is selected as the MB type, else add 0], accumulated for a basic unit [the register is double buffered so that the value read is the sum from the previous BU, whilst an internal register accumulates the sum for the current BU].
0x3AC ENCODER0_CR_BEST_INTRA_BU_COST rw
  [31:0] CR_BEST_INTRA_BU_COST — Signed sum of the best intra mode cost [including SAD, Intra cost and Intra bias] per macroblock [if Intra is selected as the MB type, else add 0], accumulated for a basic unit [the register is double buffered so that the value read is the sum from the previous BU, whilst an internal register accumulates the sum for the current BU].
0x3B0 ENCODER0_CR_PRED_COMB_DMS_SIGNATURE rw
  [31:0] CR_PRED_COMB_DMS_SIGNATURE — CRC value of the DMS predictor block
0x3B4 ENCODER0_CR_PC_DMS_PERFORMANCE_CYCLES
  [15:0] CR_PC_DMS_WORST_MB_CYCLES rw — The number of cycles taken to process the worst MB by predictor combiner.
0x3B8 ENCODER0_CR_PC_DMS_PERFORMANCE_MB_NUM
  [15:0] CR_PC_DMS_WORST_MB_NUM rw — The linear MB number of the worst MB.
0x3BC ENCODER0_CR_PC_DMS_PERFORMANCE_CTRL
  [1] CR_PC_DMS_DISABLE_COUNTERS rw
  [0] CR_PC_DMS_WORST_MB_CLEAR rw — Writing this single bit with the value '1' clears performance registers
0x3C0 ENCODER0_CR_PC_DM_PERFORMANCE_CYCLES
  [15:0] CR_PC_DM_WORST_MB_CYCLES rw — The number of cycles taken to process the worst MB by predictor combiner.
0x3C4 ENCODER0_CR_PC_DM_PERFORMANCE_MB_NUM
  [15:0] CR_PC_DM_WORST_MB_NUM rw — The linear MB number of the worst MB.
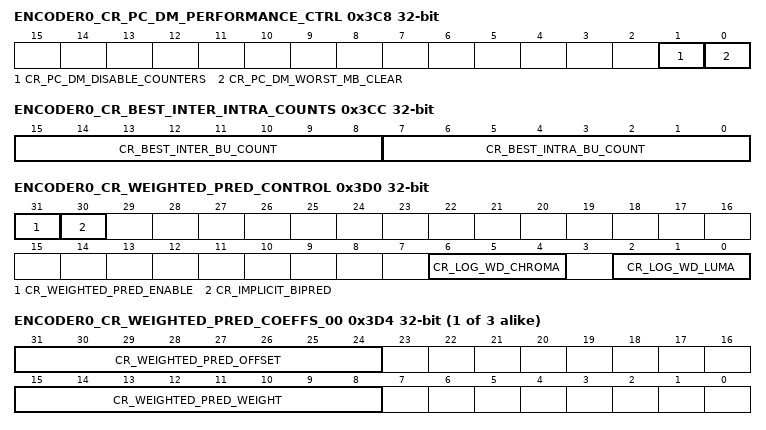
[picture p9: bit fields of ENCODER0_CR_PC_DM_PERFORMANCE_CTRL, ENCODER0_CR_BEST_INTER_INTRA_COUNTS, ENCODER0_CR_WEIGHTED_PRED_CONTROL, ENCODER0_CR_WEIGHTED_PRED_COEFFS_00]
0x3C8 ENCODER0_CR_PC_DM_PERFORMANCE_CTRL
  [1] CR_PC_DM_DISABLE_COUNTERS rw
  [0] CR_PC_DM_WORST_MB_CLEAR rw — Writing this single bit with the value '1' clears performance registers
0x3CC ENCODER0_CR_BEST_INTER_INTRA_COUNTS
  [15:8] CR_BEST_INTER_BU_COUNT rw — Number of macroblocks in a basic unit where Inter is selected as MB type [the register is double buffered, so that the value read is the count from the previous BU, whilst an internal register accumulates count for the current BU].
  [7:0] CR_BEST_INTRA_BU_COUNT rw — Number of macroblocks in a basic unit where Intra is selected as MB type [the register is double buffered, so that the value read is the count from the previous BU, whilst an internal register accumulates count for the current BU].
0x3D0 ENCODER0_CR_WEIGHTED_PRED_CONTROL
  [31] CR_WEIGHTED_PRED_ENABLE rw — Enables or disables weighted prediction
  [30] CR_IMPLICIT_BIPRED rw — H264 only, when WEIGHTED_PRED_ENABLE is set.
  [6:4] CR_LOG_WD_CHROMA rw — H264 only.
  [2:0] CR_LOG_WD_LUMA rw — H264 only.
{0x3D4+4i} ENCODER0_CR_WEIGHTED_PRED_COEFFS_{i:02} rw (i=0..2) — 0 - Luma1 - Cbpard 2 - Cr
  [31:24] CR_WEIGHTED_PRED_OFFSET — H264 only.
  [15:8] CR_WEIGHTED_PRED_WEIGHT — H264 only.
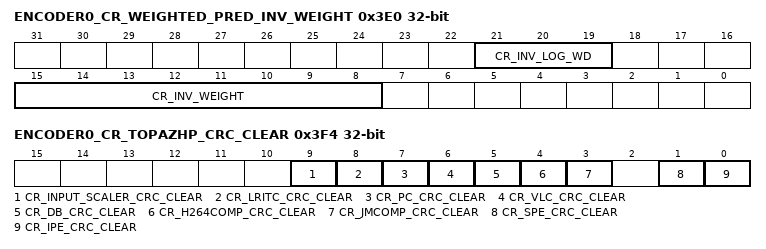
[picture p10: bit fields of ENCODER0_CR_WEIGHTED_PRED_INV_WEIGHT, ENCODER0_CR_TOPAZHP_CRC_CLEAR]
0x3E0 ENCODER0_CR_WEIGHTED_PRED_INV_WEIGHT — The inverse of the luma weight is used by SPE to weight the current picture rather than reference. For each picture, software can calculate the value to put in the register as follows;-scaled_weight = weight << (7-log_wd)scaled_inv_weight = ((1 << 14) + (scaled_weight>>1)) / scaled_weighttmp_inv_log = 7while ((abs(scaled_inv_weight) >= 128) && (tmp_inv_log > 0))( tmp_inv_log = tmp_inv_log-1 scaled_inv_weight = (scaled_inv_weight>>1))if ((tmp_inv_log == 0) && (scaled_inv_weight >= 128)) scaled_inv_weight = 127end ifinv_weight = scaled_inv_weightinv_log_wd = tmp_inv_log
  [21:19] CR_INV_LOG_WD rw — H264 only.
  [15:8] CR_INV_WEIGHT rw — H264 only.
0x3F0 ENCODER0_CR_TOPAZHP_RSVD0 rw
0x3F4 ENCODER0_CR_TOPAZHP_CRC_CLEAR — Active high resets for the CRCs.CRCs are cleared on writing the relevant bit of this register to '1'.The register bit will then self-clear.When read, this register will alway return zero.
  [9] CR_INPUT_SCALER_CRC_CLEAR rw
  [8] CR_LRITC_CRC_CLEAR rw — 0 : Has no effect
  [7] CR_PC_CRC_CLEAR rw — 0 : Has no effect
  [6] CR_VLC_CRC_CLEAR rw — 0 : Has no effect
  [5] CR_DB_CRC_CLEAR rw — 0 : Has no effect
  [4] CR_H264COMP_CRC_CLEAR rw — 0 : Has no effect
  [3] CR_JMCOMP_CRC_CLEAR rw — 0 : Has no effect
  [1] CR_SPE_CRC_CLEAR rw — 0 : Has no effect
  [0] CR_IPE_CRC_CLEAR rw — 0 : Has no effect
